# Watchdog_Timer_3 register map
Vendor: Texas Instruments
Peripheral module from a debugger description file (folder msp430).
Registers are 16-bit, read-write, reset 0x0 unless marked. A register's access mark holds for its fields unless they carry their own. Offsets are as the file gives them; lines under a group give offsets from that group; [hi:lo] are bit positions; {n}, {i} and the like mark numbered series; 'fields as' and 'values as' point back to an identical list; <NAME> marks a mode.

## Watchdog_Timer
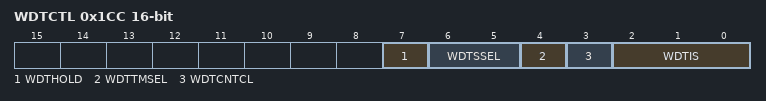
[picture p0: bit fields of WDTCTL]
0x1CC WDTCTL — Watchdog Timer Control
  [7] WDTHOLD — WDT - Timer hold
  [6:5] WDTSSEL — WDT - Timer Clock Source Select 0
    0=WDT - Timer Clock Source Select: SMCLK; 1=WDT - Timer Clock Source Select: ACLK; 2=WDT - Timer Clock Source Select: VLO_CLK; 3=WDT - Timer Clock Source Select: reserved
  [4] WDTTMSEL — WDT - Timer Mode Select
  [3] WDTCNTCL — WDT - Timer Clear
  [2:0] WDTIS — WDT - Timer Interval Select 0
    0=WDT - Timer Interval Select: /2G; 1=WDT - Timer Interval Select: /128M; 2=WDT - Timer Interval Select: /8192k; 3=WDT - Timer Interval Select: /512k; 4=WDT - Timer Interval Select: /32k; 5=WDT - Timer Interval Select: /8192; 6=WDT - Timer Interval Select: /512; 7=WDT - Timer Interval Select: /64
